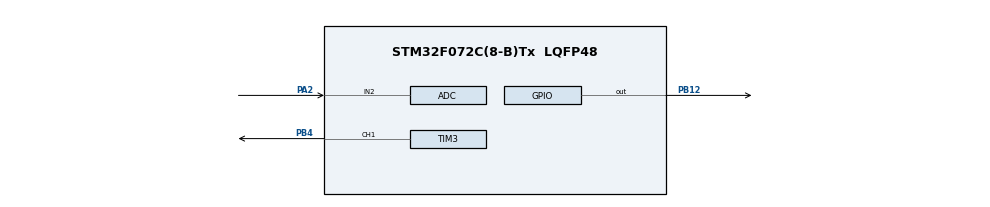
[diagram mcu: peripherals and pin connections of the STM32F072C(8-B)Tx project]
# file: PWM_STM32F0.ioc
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Mcu.Family=STM32F0
Mcu.Name=STM32F072C(8-B)Tx
Mcu.Package=LQFP48
PA2.Mode=IN2
PA2.Signal=ADC_IN2
PB12.Signal=GPIO_Output
PB4.Signal=S_TIM3_CH1
ProjectManager.HeapSize=0x200
ProjectManager.StackSize=0x400
ProjectManager.TargetToolchain=STM32CubeIDE
SH.S_TIM3_CH1.0=TIM3_CH1,PWM Generation1 CH1
TIM3.Channel-PWM\ Generation1\ CH1=TIM_CHANNEL_1
TIM3.Period=100
TIM3.Prescaler=16
TIM3.Pulse-PWM\ Generation1\ CH1=50
VP_TIM3_VS_ClockSourceINT.Mode=Internal
board=custom

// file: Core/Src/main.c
/* USER CODE BEGIN Header */
/**
  ******************************************************************************
  * @file           : main.c
  * @brief          : Main program body
  ******************************************************************************
  * @attention
  *
  * <h2><center>&copy; Copyright (c) 2021 STMicroelectronics.
  * All rights reserved.</center></h2>
  *
  * This software component is licensed by ST under BSD 3-Clause license,
  * the "License"; You may not use this file except in compliance with the
  * License. You may obtain a copy of the License at:
  *                        opensource.org/licenses/BSD-3-Clause
  *
  ******************************************************************************
  */
/* USER CODE END Header */
#include "main.h"

ADC_HandleTypeDef hadc;

TIM_HandleTypeDef htim3;

void SystemClock_Config(void);
static void MX_GPIO_Init(void);
static void MX_ADC_Init(void);
static void MX_TIM3_Init(void);

int main(void)
{

  /* MCU Configuration--------------------------------------------------------*/

  /* Reset of all peripherals, Initializes the Flash interface and the Systick. */
  HAL_Init();

  /* Configure the system clock */
  SystemClock_Config();

  /* Initialize all configured peripherals */
  MX_GPIO_Init();
  MX_ADC_Init();
  MX_TIM3_Init();
  /* USER CODE BEGIN 2 */

  HAL_TIM_Base_Start(&htim3);
  HAL_TIM_PWM_Start(&htim3, TIM_CHANNEL_1);
  int high = 0;

  /* USER CODE END 2 */

  /* Infinite loop */
  /* USER CODE BEGIN WHILE */
  while (1)
  {
	  // Start ADC Conversion
	  	  HAL_ADC_Start(&hadc);
	  	  // Poll ADC1 Perihperal & TimeOut = 1mSec
	  	  HAL_ADC_PollForConversion(&hadc, 1);
	  	  // Read The ADC Conversion Result & Map It To PWM DutyCycle
	  	  uint16_t ang = HAL_ADC_GetValue(&hadc);

	  	  uint16_t analog = ang*3300/(1<<12);

	  	  HAL_Delay(2000);
	  	  __HAL_TIM_SET_COMPARE(&htim3, TIM_CHANNEL_1, analog/3.33*100);
    /* USER CODE END WHILE */

  }
}

void SystemClock_Config(void)
{
  RCC_OscInitTypeDef RCC_OscInitStruct = {0};
  RCC_ClkInitTypeDef RCC_ClkInitStruct = {0};

  /** Initializes the RCC Oscillators according to the specified parameters
  * in the RCC_OscInitTypeDef structure.
  */
  RCC_OscInitStruct.OscillatorType = RCC_OSCILLATORTYPE_HSI|RCC_OSCILLATORTYPE_HSI14;
  RCC_OscInitStruct.HSIState = RCC_HSI_ON;
  RCC_OscInitStruct.HSI14State = RCC_HSI14_ON;
  RCC_OscInitStruct.HSICalibrationValue = RCC_HSICALIBRATION_DEFAULT;
  RCC_OscInitStruct.HSI14CalibrationValue = 16;
  RCC_OscInitStruct.PLL.PLLState = RCC_PLL_NONE;
  if (HAL_RCC_OscConfig(&RCC_OscInitStruct) != HAL_OK)
  {
    Error_Handler();
  }
  /** Initializes the CPU, AHB and APB buses clocks
  */
  RCC_ClkInitStruct.ClockType = RCC_CLOCKTYPE_HCLK|RCC_CLOCKTYPE_SYSCLK
                              |RCC_CLOCKTYPE_PCLK1;
  RCC_ClkInitStruct.SYSCLKSource = RCC_SYSCLKSOURCE_HSI;
  RCC_ClkInitStruct.AHBCLKDivider = RCC_SYSCLK_DIV1;
  RCC_ClkInitStruct.APB1CLKDivider = RCC_HCLK_DIV1;

  if (HAL_RCC_ClockConfig(&RCC_ClkInitStruct, FLASH_LATENCY_0) != HAL_OK)
  {
    Error_Handler();
  }
}

static void MX_ADC_Init(void)
{

  ADC_ChannelConfTypeDef sConfig = {0};

  /** Configure the global features of the ADC (Clock, Resolution, Data Alignment and number of conversion)
  */
  hadc.Instance = ADC1;
  hadc.Init.ClockPrescaler = ADC_CLOCK_ASYNC_DIV1;
  hadc.Init.Resolution = ADC_RESOLUTION_12B;
  hadc.Init.DataAlign = ADC_DATAALIGN_RIGHT;
  hadc.Init.ScanConvMode = ADC_SCAN_DIRECTION_FORWARD;
  hadc.Init.EOCSelection = ADC_EOC_SINGLE_CONV;
  hadc.Init.LowPowerAutoWait = DISABLE;
  hadc.Init.LowPowerAutoPowerOff = DISABLE;
  hadc.Init.ContinuousConvMode = DISABLE;
  hadc.Init.DiscontinuousConvMode = DISABLE;
  hadc.Init.ExternalTrigConv = ADC_SOFTWARE_START;
  hadc.Init.ExternalTrigConvEdge = ADC_EXTERNALTRIGCONVEDGE_NONE;
  hadc.Init.DMAContinuousRequests = DISABLE;
  hadc.Init.Overrun = ADC_OVR_DATA_PRESERVED;
  if (HAL_ADC_Init(&hadc) != HAL_OK)
  {
    Error_Handler();
  }
  /** Configure for the selected ADC regular channel to be converted.
  */
  sConfig.Channel = ADC_CHANNEL_2;
  sConfig.Rank = ADC_RANK_CHANNEL_NUMBER;
  sConfig.SamplingTime = ADC_SAMPLETIME_1CYCLE_5;
  if (HAL_ADC_ConfigChannel(&hadc, &sConfig) != HAL_OK)
  {
    Error_Handler();
  }

}

static void MX_TIM3_Init(void)
{

  TIM_ClockConfigTypeDef sClockSourceConfig = {0};
  TIM_MasterConfigTypeDef sMasterConfig = {0};
  TIM_OC_InitTypeDef sConfigOC = {0};

  htim3.Instance = TIM3;
  htim3.Init.Prescaler = 16;
  htim3.Init.CounterMode = TIM_COUNTERMODE_UP;
  htim3.Init.Period = 100;
  htim3.Init.ClockDivision = TIM_CLOCKDIVISION_DIV1;
  htim3.Init.AutoReloadPreload = TIM_AUTORELOAD_PRELOAD_DISABLE;
  if (HAL_TIM_Base_Init(&htim3) != HAL_OK)
  {
    Error_Handler();
  }
  sClockSourceConfig.ClockSource = TIM_CLOCKSOURCE_INTERNAL;
  if (HAL_TIM_ConfigClockSource(&htim3, &sClockSourceConfig) != HAL_OK)
  {
    Error_Handler();
  }
  if (HAL_TIM_PWM_Init(&htim3) != HAL_OK)
  {
    Error_Handler();
  }
  sMasterConfig.MasterOutputTrigger = TIM_TRGO_RESET;
  sMasterConfig.MasterSlaveMode = TIM_MASTERSLAVEMODE_DISABLE;
  if (HAL_TIMEx_MasterConfigSynchronization(&htim3, &sMasterConfig) != HAL_OK)
  {
    Error_Handler();
  }
  sConfigOC.OCMode = TIM_OCMODE_PWM1;
  sConfigOC.Pulse = 50;
  sConfigOC.OCPolarity = TIM_OCPOLARITY_HIGH;
  sConfigOC.OCFastMode = TIM_OCFAST_DISABLE;
  if (HAL_TIM_PWM_ConfigChannel(&htim3, &sConfigOC, TIM_CHANNEL_1) != HAL_OK)
  {
    Error_Handler();
  }
  HAL_TIM_MspPostInit(&htim3);

}

static void MX_GPIO_Init(void)
{
  GPIO_InitTypeDef GPIO_InitStruct = {0};

  /* GPIO Ports Clock Enable */
  __HAL_RCC_GPIOA_CLK_ENABLE();
  __HAL_RCC_GPIOB_CLK_ENABLE();

  /*Configure GPIO pin Output Level */
  HAL_GPIO_WritePin(GPIOB, GPIO_PIN_12, GPIO_PIN_RESET);

  /*Configure GPIO pin : PB12 */
  GPIO_InitStruct.Pin = GPIO_PIN_12;
  GPIO_InitStruct.Mode = GPIO_MODE_OUTPUT_PP;
  GPIO_InitStruct.Pull = GPIO_NOPULL;
  GPIO_InitStruct.Speed = GPIO_SPEED_FREQ_LOW;
  HAL_GPIO_Init(GPIOB, &GPIO_InitStruct);

}

void Error_Handler(void)
{
  /* USER CODE BEGIN Error_Handler_Debug */
  /* User can add his own implementation to report the HAL error return state */
	HAL_GPIO_TogglePin (GPIOB, GPIO_PIN_12);
	//HAL_Delay(500);
  /* USER CODE END Error_Handler_Debug */
}

/************************ (C) COPYRIGHT STMicroelectronics *****END OF FILE****/
